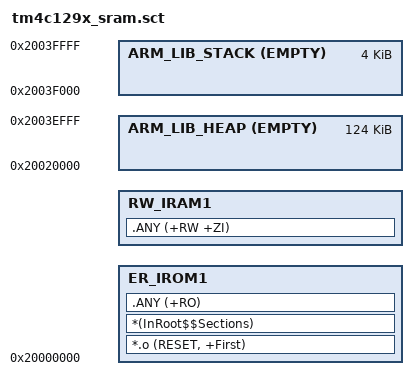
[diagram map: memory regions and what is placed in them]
;******************************************************************
;* TM4C129X linker scatter file (running code from internal SRAM) *
;******************************************************************

LR_IROM1 0x20000000 0x40000
{
   ER_IROM1 0x20000000
   {
      *.o (RESET, +First)
      *(InRoot$$Sections)
      .ANY (+RO)
   }
   
   RW_IRAM1 +0
   { 
      .ANY (+RW +ZI)
   }
   
   ScatterAssert((ImageLength(ER_IROM1) + ImageLength(RW_IRAM1)) < 0x20000)
   
   ARM_LIB_STACK 0x20040000 EMPTY -0x1000
   {
   }
   
   ARM_LIB_HEAP 0x20020000 EMPTY 0x1F000
   {
   }
}
